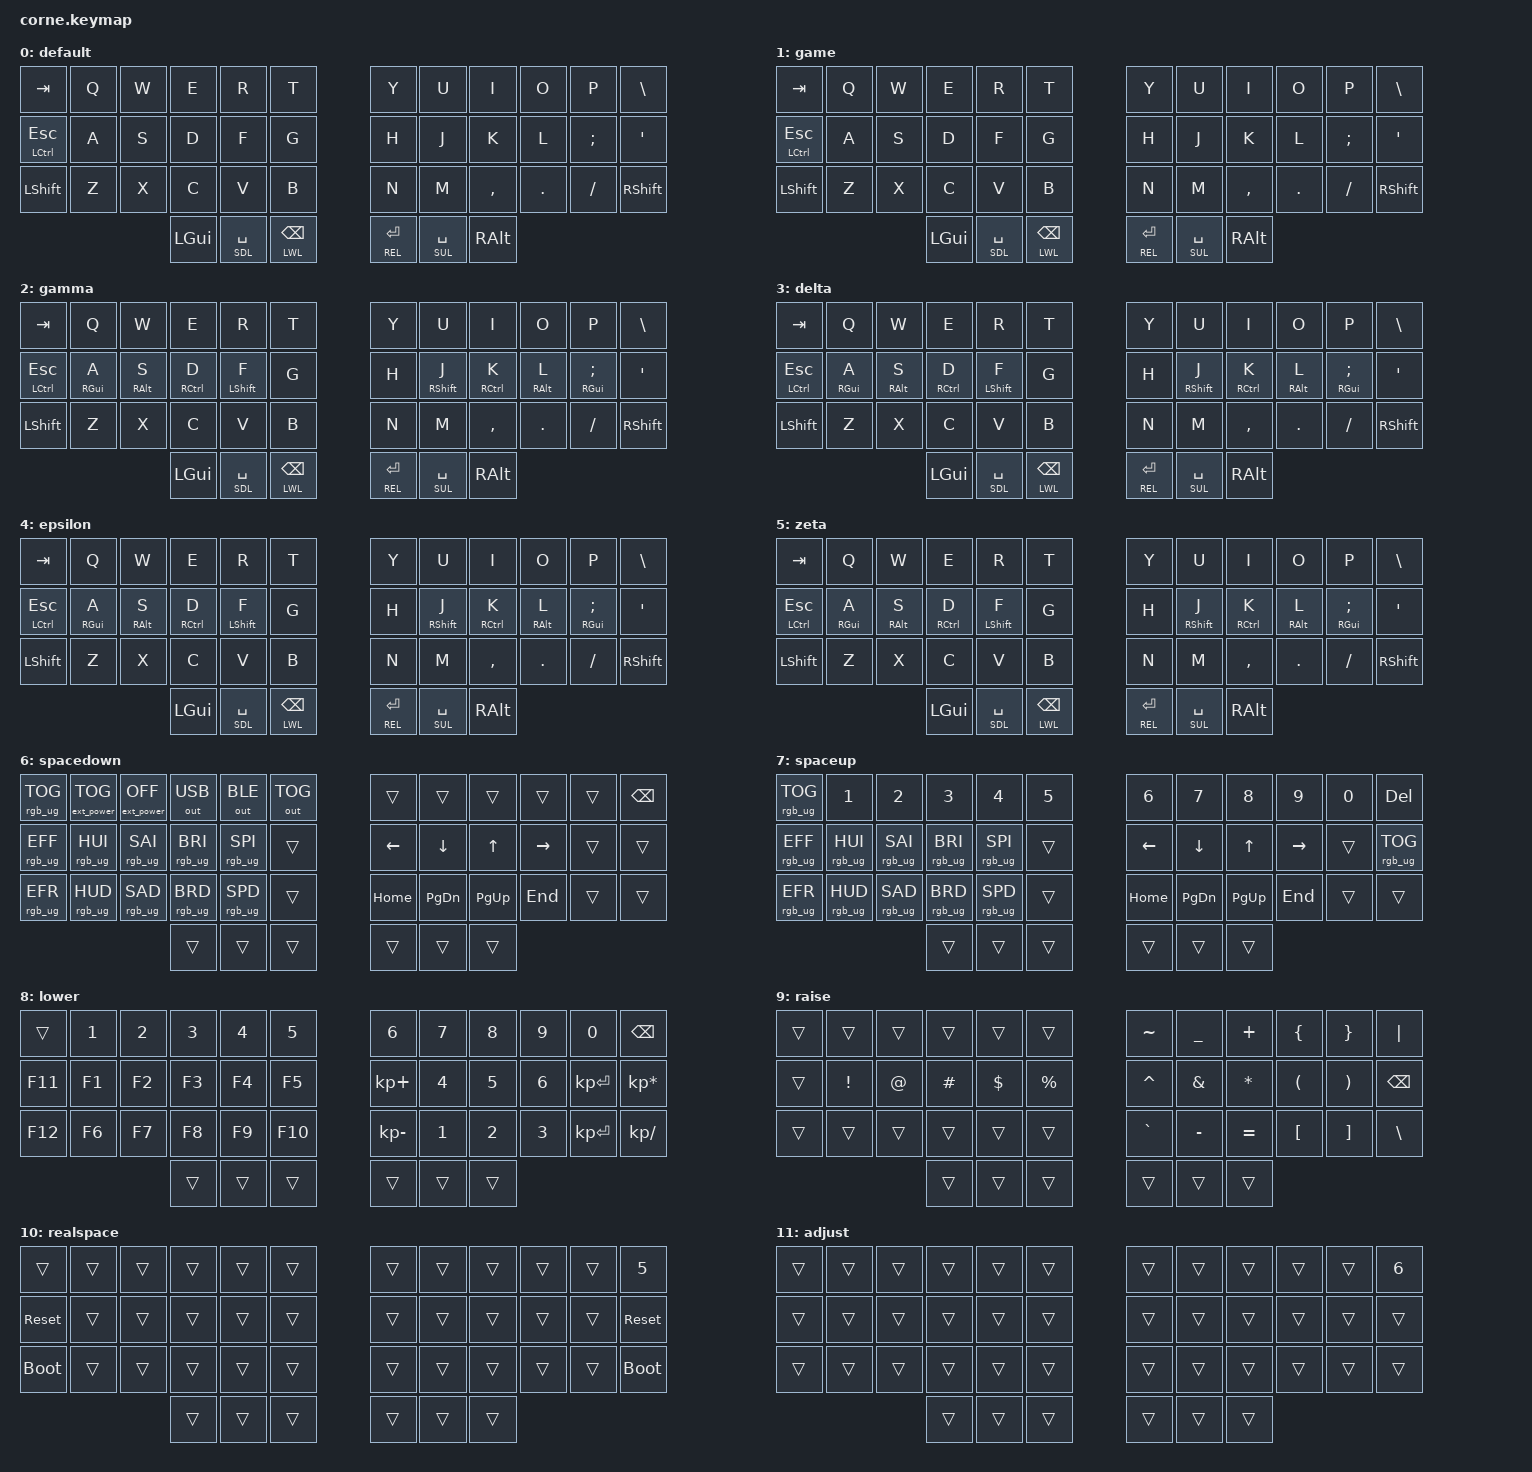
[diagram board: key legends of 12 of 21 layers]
/*
 * Copyright (c) 2020-2022 The ZMK Contributors
 *
 * SPDX-License-Identifier: MIT
 */

#include "behaviors.dtsi"
#include "dt-bindings/zmk/keys.h"

#include "dt-bindings/zmk/bt.h"
#include "dt-bindings/zmk/mouse.h"
#include "dt-bindings/zmk/outputs.h"
#include "dt-bindings/zmk/ext_power.h"
#include "dt-bindings/zmk/rgb.h"

#include "zmk-helpers/helper.h"
#include "zmk-helpers/key-labels/42.h"

#define DFL  0
#define GML  1
#define GAL  2
#define DTL  3
#define EPL  4
#define ZEL  5
#define SDL  6
#define SUL  7
#define LWL  8
#define REL  9
#define RSL 10
#define AJL 11
#define SSL 12
#define HSL 13
#define KSL 14
#define CSL 15
#define SLL 16
#define FSL 17
#define BHL 18
#define WHL 19
#define WPL 20

&spi3 {
  led_strip: ws2812@0 {
    /* WS2812 */
    chain-length = <27>; /* There are per-key RGB, but the first 6 are underglow */
  };
};

&mt {
  tapping-term-ms = <180>;
  flavor = "tap-preferred";
};
&lt {
  quick-tap-ms = <180>;
  tapping-term-ms = <200>;
  flavor = "balanced";
};

ZMK_CONDITIONAL_LAYER(SDL SUL, RSL) // spacedown + spaceup = realspace
ZMK_CONDITIONAL_LAYER(LWL REL, AJL) // lower + raise = adjust
ZMK_CONDITIONAL_LAYER(SDL LWL, SSL) // spacedown + lower = subspace
ZMK_CONDITIONAL_LAYER(SUL REL, HSL) // spaceup + raise = hyperspace
ZMK_CONDITIONAL_LAYER(SDL REL, KSL) // spacedown + raise = knownspace
ZMK_CONDITIONAL_LAYER(LWL SUL, CSL) // lower + spaceup = cyberspace
ZMK_CONDITIONAL_LAYER(SSL REL, SLL) // subspace + raise = slipspace
ZMK_CONDITIONAL_LAYER(LWL HSL, FSL) // lower + hyperspace = foldspace
ZMK_CONDITIONAL_LAYER(SSL SUL, BHL) // subspace + spaceup = blackhole
ZMK_CONDITIONAL_LAYER(SDL HSL, WHL) // spacedown + hyperspace = whitehole
ZMK_CONDITIONAL_LAYER(SSL HSL, WPL) // subspace + hyperspace = warp

ZMK_LAYER(default,
//    ┌───────────────┬───────┬───────┬──────────┬───────────────┬──────────────┬─────────────┬───────────────┬───────────┬─────────┬──────────┬───────────┐
        &kp TAB         &kp Q   &kp W   &kp E      &kp R           &kp T          &kp Y         &kp U           &kp I       &kp O     &kp P      &kp BSLH
//    ├───────────────┼───────┼───────┼──────────┼───────────────┼──────────────┼─────────────┼───────────────┼───────────┼─────────┼──────────┼───────────┤
        &mt LCTRL ESC   &kp A   &kp S   &kp D      &kp F           &kp G          &kp H         &kp J           &kp K       &kp L     &kp SEMI   &kp SQT
//    ├───────────────┼───────┼───────┼──────────┼───────────────┼──────────────┼─────────────┼───────────────┼───────────┼─────────┼──────────┼───────────┤
        &kp LSHFT       &kp Z   &kp X   &kp C      &kp V           &kp B          &kp N         &kp M           &kp COMMA   &kp DOT   &kp FSLH   &kp RSHFT
//    └───────────────┴───────┴───────┼──────────┼───────────────┼──────────────┼─────────────┼───────────────┼───────────┼─────────┴──────────┴───────────┘
                                        &kp LGUI   &lt SDL SPACE   &lt LWL BSPC   &lt REL RET   &lt SUL SPACE   &kp RALT
//                                    └──────────┴───────────────┴──────────────┴─────────────┴───────────────┴───────────┘
)

ZMK_LAYER(game,
//    ┌───────────────┬───────┬───────┬──────────┬───────────────┬──────────────┬─────────────┬───────────────┬───────────┬─────────┬──────────┬───────────┐
        &kp TAB         &kp Q   &kp W   &kp E      &kp R           &kp T          &kp Y         &kp U           &kp I       &kp O     &kp P      &kp BSLH
//    ├───────────────┼───────┼───────┼──────────┼───────────────┼──────────────┼─────────────┼───────────────┼───────────┼─────────┼──────────┼───────────┤
        &mt LCTRL ESC   &kp A   &kp S   &kp D      &kp F           &kp G          &kp H         &kp J           &kp K       &kp L     &kp SEMI   &kp SQT
//    ├───────────────┼───────┼───────┼──────────┼───────────────┼──────────────┼─────────────┼───────────────┼───────────┼─────────┼──────────┼───────────┤
        &kp LSHFT       &kp Z   &kp X   &kp C      &kp V           &kp B          &kp N         &kp M           &kp COMMA   &kp DOT   &kp FSLH   &kp RSHFT
//    └───────────────┴───────┴───────┼──────────┼───────────────┼──────────────┼─────────────┼───────────────┼───────────┼─────────┴──────────┴───────────┘
                                        &kp LGUI   &lt SDL SPACE   &lt LWL BSPC   &lt REL RET   &lt SUL SPACE   &kp RALT
//                                    └──────────┴───────────────┴──────────────┴─────────────┴───────────────┴───────────┘
)

ZMK_LAYER(gamma,
//    ┌───────────────┬────────────┬────────────┬─────────────┬───────────────┬──────────────┬─────────────┬───────────────┬─────────────┬────────────┬───────────────┬───────────┐
        &kp TAB         &kp Q        &kp W        &kp E         &kp R           &kp T          &kp Y         &kp U           &kp I         &kp O        &kp P           &kp BSLH
//    ├───────────────┼────────────┼────────────┼─────────────┼───────────────┼──────────────┼─────────────┼───────────────┼─────────────┼────────────┼───────────────┼───────────┤
        &mt LCTRL ESC   &mt RGUI A   &mt RALT S   &mt RCTRL D   &mt LSHFT F     &kp G          &kp H         &mt RSHFT J     &mt RCTRL K   &mt RALT L   &mt RGUI SEMI   &kp SQT
//    ├───────────────┼────────────┼────────────┼─────────────┼───────────────┼──────────────┼─────────────┼───────────────┼─────────────┼────────────┼───────────────┼───────────┤
        &kp LSHFT       &kp Z        &kp X        &kp C         &kp V           &kp B          &kp N         &kp M           &kp COMMA     &kp DOT      &kp FSLH        &kp RSHFT
//    └───────────────┴────────────┴────────────┼─────────────┼───────────────┼──────────────┼─────────────┼───────────────┼─────────────┼────────────┴───────────────┴───────────┘
                                                  &kp LGUI      &lt SDL SPACE   &lt LWL BSPC   &lt REL RET   &lt SUL SPACE   &kp RALT
//                                              └─────────────┴───────────────┴──────────────┴─────────────┴───────────────┴─────────────┘
)

ZMK_LAYER(delta,
//    ┌───────────────┬────────────┬────────────┬─────────────┬───────────────┬──────────────┬─────────────┬───────────────┬─────────────┬────────────┬───────────────┬───────────┐
        &kp TAB         &kp Q        &kp W        &kp E         &kp R           &kp T          &kp Y         &kp U           &kp I         &kp O        &kp P           &kp BSLH
//    ├───────────────┼────────────┼────────────┼─────────────┼───────────────┼──────────────┼─────────────┼───────────────┼─────────────┼────────────┼───────────────┼───────────┤
        &mt LCTRL ESC   &mt RGUI A   &mt RALT S   &mt RCTRL D   &mt LSHFT F     &kp G          &kp H         &mt RSHFT J     &mt RCTRL K   &mt RALT L   &mt RGUI SEMI   &kp SQT
//    ├───────────────┼────────────┼────────────┼─────────────┼───────────────┼──────────────┼─────────────┼───────────────┼─────────────┼────────────┼───────────────┼───────────┤
        &kp LSHFT       &kp Z        &kp X        &kp C         &kp V           &kp B          &kp N         &kp M           &kp COMMA     &kp DOT      &kp FSLH        &kp RSHFT
//    └───────────────┴────────────┴────────────┼─────────────┼───────────────┼──────────────┼─────────────┼───────────────┼─────────────┼────────────┴───────────────┴───────────┘
                                                  &kp LGUI      &lt SDL SPACE   &lt LWL BSPC   &lt REL RET   &lt SUL SPACE   &kp RALT
//                                              └─────────────┴───────────────┴──────────────┴─────────────┴───────────────┴─────────────┘
)

ZMK_LAYER(epsilon,
//    ┌───────────────┬────────────┬────────────┬─────────────┬───────────────┬──────────────┬─────────────┬───────────────┬─────────────┬────────────┬───────────────┬───────────┐
        &kp TAB         &kp Q        &kp W        &kp E         &kp R           &kp T          &kp Y         &kp U           &kp I         &kp O        &kp P           &kp BSLH
//    ├───────────────┼────────────┼────────────┼─────────────┼───────────────┼──────────────┼─────────────┼───────────────┼─────────────┼────────────┼───────────────┼───────────┤
        &mt LCTRL ESC   &mt RGUI A   &mt RALT S   &mt RCTRL D   &mt LSHFT F     &kp G          &kp H         &mt RSHFT J     &mt RCTRL K   &mt RALT L   &mt RGUI SEMI   &kp SQT
//    ├───────────────┼────────────┼────────────┼─────────────┼───────────────┼──────────────┼─────────────┼───────────────┼─────────────┼────────────┼───────────────┼───────────┤
        &kp LSHFT       &kp Z        &kp X        &kp C         &kp V           &kp B          &kp N         &kp M           &kp COMMA     &kp DOT      &kp FSLH        &kp RSHFT
//    └───────────────┴────────────┴────────────┼─────────────┼───────────────┼──────────────┼─────────────┼───────────────┼─────────────┼────────────┴───────────────┴───────────┘
                                                  &kp LGUI      &lt SDL SPACE   &lt LWL BSPC   &lt REL RET   &lt SUL SPACE   &kp RALT
//                                              └─────────────┴───────────────┴──────────────┴─────────────┴───────────────┴─────────────┘
)

ZMK_LAYER(zeta,
//    ┌───────────────┬────────────┬────────────┬─────────────┬───────────────┬──────────────┬─────────────┬───────────────┬─────────────┬────────────┬───────────────┬───────────┐
        &kp TAB         &kp Q        &kp W        &kp E         &kp R           &kp T          &kp Y         &kp U           &kp I         &kp O        &kp P           &kp BSLH
//    ├───────────────┼────────────┼────────────┼─────────────┼───────────────┼──────────────┼─────────────┼───────────────┼─────────────┼────────────┼───────────────┼───────────┤
        &mt LCTRL ESC   &mt RGUI A   &mt RALT S   &mt RCTRL D   &mt LSHFT F     &kp G          &kp H         &mt RSHFT J     &mt RCTRL K   &mt RALT L   &mt RGUI SEMI   &kp SQT
//    ├───────────────┼────────────┼────────────┼─────────────┼───────────────┼──────────────┼─────────────┼───────────────┼─────────────┼────────────┼───────────────┼───────────┤
        &kp LSHFT       &kp Z        &kp X        &kp C         &kp V           &kp B          &kp N         &kp M           &kp COMMA     &kp DOT      &kp FSLH        &kp RSHFT
//    └───────────────┴────────────┴────────────┼─────────────┼───────────────┼──────────────┼─────────────┼───────────────┼─────────────┼────────────┴───────────────┴───────────┘
                                                  &kp LGUI      &lt SDL SPACE   &lt LWL BSPC   &lt REL RET   &lt SUL SPACE   &kp RALT
//                                              └─────────────┴───────────────┴──────────────┴─────────────┴───────────────┴─────────────┘
)

ZMK_LAYER(spacedown,
//    ┌─────────────────┬───────────────────┬───────────────────┬─────────────────┬─────────────────┬──────────────┬──────────┬───────────┬───────────┬───────────┬────────┬──────────┐
        &rgb_ug RGB_TOG   &ext_power EP_TOG   &ext_power EP_OFF   &out OUT_USB      &out OUT_BLE      &out OUT_TOG   &trans     &trans      &trans      &trans      &trans   &kp BSPC
//    ├─────────────────┼───────────────────┼───────────────────┼─────────────────┼─────────────────┼──────────────┼──────────┼───────────┼───────────┼───────────┼────────┼──────────┤
        &rgb_ug RGB_EFF   &rgb_ug RGB_HUI     &rgb_ug RGB_SAI     &rgb_ug RGB_BRI   &rgb_ug RGB_SPI   &trans         &kp LEFT   &kp DOWN    &kp UP      &kp RIGHT   &trans   &trans
//    ├─────────────────┼───────────────────┼───────────────────┼─────────────────┼─────────────────┼──────────────┼──────────┼───────────┼───────────┼───────────┼────────┼──────────┤
        &rgb_ug RGB_EFR   &rgb_ug RGB_HUD     &rgb_ug RGB_SAD     &rgb_ug RGB_BRD   &rgb_ug RGB_SPD   &trans         &kp HOME   &kp PG_DN   &kp PG_UP   &kp END     &trans   &trans
//    └─────────────────┴───────────────────┴───────────────────┼─────────────────┼─────────────────┼──────────────┼──────────┼───────────┼───────────┼───────────┴────────┴──────────┘
                                                                  &trans            &trans            &trans         &trans     &trans      &trans
//                                                              └─────────────────┴─────────────────┴──────────────┴──────────┴───────────┴───────────┘
)

ZMK_LAYER(spaceup,
//    ┌─────────────────┬─────────────────┬─────────────────┬─────────────────┬─────────────────┬────────┬──────────┬───────────┬───────────┬───────────┬────────┬─────────────────┐
        &rgb_ug RGB_TOG   &kp N1            &kp N2            &kp N3            &kp N4            &kp N5   &kp N6     &kp N7      &kp N8      &kp N9      &kp N0   &kp DEL
//    ├─────────────────┼─────────────────┼─────────────────┼─────────────────┼─────────────────┼────────┼──────────┼───────────┼───────────┼───────────┼────────┼─────────────────┤
        &rgb_ug RGB_EFF   &rgb_ug RGB_HUI   &rgb_ug RGB_SAI   &rgb_ug RGB_BRI   &rgb_ug RGB_SPI   &trans   &kp LEFT   &kp DOWN    &kp UP      &kp RIGHT   &trans   &rgb_ug RGB_TOG
//    ├─────────────────┼─────────────────┼─────────────────┼─────────────────┼─────────────────┼────────┼──────────┼───────────┼───────────┼───────────┼────────┼─────────────────┤
        &rgb_ug RGB_EFR   &rgb_ug RGB_HUD   &rgb_ug RGB_SAD   &rgb_ug RGB_BRD   &rgb_ug RGB_SPD   &trans   &kp HOME   &kp PG_DN   &kp PG_UP   &kp END     &trans   &trans
//    └─────────────────┴─────────────────┴─────────────────┼─────────────────┼─────────────────┼────────┼──────────┼───────────┼───────────┼───────────┴────────┴─────────────────┘
                                                              &trans            &trans            &trans   &trans     &trans      &trans
//                                                          └─────────────────┴─────────────────┴────────┴──────────┴───────────┴───────────┘                                       
)

ZMK_LAYER(lower,
//    ┌─────────┬────────┬────────┬────────┬────────┬─────────┬──────────────┬────────┬────────┬────────┬──────────────┬─────────────────┐
        &trans    &kp N1   &kp N2   &kp N3   &kp N4   &kp N5    &kp N6         &kp N7   &kp N8   &kp N9   &kp N0         &kp BSPC
//    ├─────────┼────────┼────────┼────────┼────────┼─────────┼──────────────┼────────┼────────┼────────┼──────────────┼─────────────────┤
        &kp F11   &kp F1   &kp F2   &kp F3   &kp F4   &kp F5    &kp KP_PLUS    &kp N4   &kp N5   &kp N6   &kp KP_ENTER   &kp KP_MULTIPLY
//    ├─────────┼────────┼────────┼────────┼────────┼─────────┼──────────────┼────────┼────────┼────────┼──────────────┼─────────────────┤
        &kp F12   &kp F6   &kp F7   &kp F8   &kp F9   &kp F10   &kp KP_MINUS   &kp N1   &kp N2   &kp N3   &kp KP_ENTER   &kp KP_DIVIDE
//    └─────────┴────────┴────────┼────────┼────────┼─────────┼──────────────┼────────┼────────┼────────┴──────────────┴─────────────────┘
                                    &trans   &trans   &trans    &trans         &trans   &trans
//                                └────────┴────────┴─────────┴──────────────┴────────┴────────┘
)

ZMK_LAYER(raise,
//    ┌────────┬──────────┬────────┬──────────┬──────────┬───────────┬───────────┬───────────┬───────────┬──────────┬──────────┬──────────┐
        &trans   &trans     &trans   &trans     &trans     &trans      &kp TILDE   &kp UNDER   &kp PLUS    &kp LBRC   &kp RBRC   &kp PIPE
//    ├────────┼──────────┼────────┼──────────┼──────────┼───────────┼───────────┼───────────┼───────────┼──────────┼──────────┼──────────┤
        &trans   &kp EXCL   &kp AT   &kp HASH   &kp DLLR   &kp PRCNT   &kp CARET   &kp AMPS    &kp ASTRK   &kp LPAR   &kp RPAR   &kp BSPC
//    ├────────┼──────────┼────────┼──────────┼──────────┼───────────┼───────────┼───────────┼───────────┼──────────┼──────────┼──────────┤
        &trans   &trans     &trans   &trans     &trans     &trans      &kp GRAVE   &kp MINUS   &kp EQUAL   &kp LBKT   &kp RBKT   &kp BSLH
//    └────────┴──────────┴────────┼──────────┼──────────┼───────────┼───────────┼───────────┼───────────┼──────────┴──────────┴──────────┘
                                     &trans     &trans     &trans      &trans      &trans      &trans
//                                 └──────────┴──────────┴───────────┴───────────┴───────────┴───────────┘
)

ZMK_LAYER(realspace,
//    ┌─────────────┬────────┬────────┬────────┬────────┬────────┬────────┬────────┬────────┬────────┬────────┬─────────────┐
        &trans        &trans   &trans   &trans   &trans   &trans   &trans   &trans   &trans   &trans   &trans   &kp N5
//    ├─────────────┼────────┼────────┼────────┼────────┼────────┼────────┼────────┼────────┼────────┼────────┼─────────────┤
        &sys_reset    &trans   &trans   &trans   &trans   &trans   &trans   &trans   &trans   &trans   &trans   &sys_reset
//    ├─────────────┼────────┼────────┼────────┼────────┼────────┼────────┼────────┼────────┼────────┼────────┼─────────────┤
        &bootloader   &trans   &trans   &trans   &trans   &trans   &trans   &trans   &trans   &trans   &trans   &bootloader
//    └─────────────┴────────┴────────┼────────┼────────┼────────┼────────┼────────┼────────┼────────┴────────┴─────────────┘
                                        &trans   &trans   &trans   &trans   &trans   &trans
//                                    └────────┴────────┴────────┴────────┴────────┴────────┘
)

ZMK_LAYER(adjust,
//    ┌────────┬────────┬────────┬────────┬────────┬────────┬────────┬────────┬────────┬────────┬────────┬────────┐
        &trans   &trans   &trans   &trans   &trans   &trans   &trans   &trans   &trans   &trans   &trans   &kp N6
//    ├────────┼────────┼────────┼────────┼────────┼────────┼────────┼────────┼────────┼────────┼────────┼────────┤
        &trans   &trans   &trans   &trans   &trans   &trans   &trans   &trans   &trans   &trans   &trans   &trans
//    ├────────┼────────┼────────┼────────┼────────┼────────┼────────┼────────┼────────┼────────┼────────┼────────┤
        &trans   &trans   &trans   &trans   &trans   &trans   &trans   &trans   &trans   &trans   &trans   &trans
//    └────────┴────────┴────────┼────────┼────────┼────────┼────────┼────────┼────────┼────────┴────────┴────────┘
                                   &trans   &trans   &trans   &trans   &trans   &trans
//                               └────────┴────────┴────────┴────────┴────────┴────────┘
)

ZMK_LAYER(subspace,
//    ┌─────────────────┬──────────────┬──────────────┬──────────────┬──────────────┬──────────────┬────────┬────────┬────────┬────────┬────────┬────────┐
        &rgb_ug RGB_TOG   &trans         &trans         &out OUT_USB   &out OUT_BLE   &out OUT_TOG   &trans   &trans   &trans   &trans   &trans   &kp N7
//    ├─────────────────┼──────────────┼──────────────┼──────────────┼──────────────┼──────────────┼────────┼────────┼────────┼────────┼────────┼────────┤
        &bt BT_CLR        &bt BT_SEL 0   &bt BT_SEL 1   &bt BT_SEL 2   &bt BT_SEL 3   &bt BT_SEL 4   &trans   &trans   &trans   &trans   &trans   &trans
//    ├─────────────────┼──────────────┼──────────────┼──────────────┼──────────────┼──────────────┼────────┼────────┼────────┼────────┼────────┼────────┤
        &trans            &bt BT_SEL 5   &bt BT_SEL 6   &bt BT_SEL 7   &bt BT_SEL 8   &bt BT_SEL 9   &trans   &trans   &trans   &trans   &trans   &trans
//    └─────────────────┴──────────────┴──────────────┼──────────────┼──────────────┼──────────────┼────────┼────────┼────────┼────────┴────────┴────────┘
                                                        &trans         &trans         &trans         &trans   &trans   &trans
//                                                    └──────────────┴──────────────┴──────────────┴────────┴────────┴────────┘
)

ZMK_LAYER(hyperspace,
//    ┌─────────────────┬─────────────────┬─────────────────┬─────────────────┬─────────────────┬────────┬──────────┬───────────┬───────────┬───────────┬────────┬────────┐
        &rgb_ug RGB_TOG   &trans            &trans            &trans            &trans            &trans   &trans     &trans      &trans      &trans      &trans   &kp N8
//    ├─────────────────┼─────────────────┼─────────────────┼─────────────────┼─────────────────┼────────┼──────────┼───────────┼───────────┼───────────┼────────┼────────┤
        &rgb_ug RGB_EFF   &rgb_ug RGB_HUI   &rgb_ug RGB_SAI   &rgb_ug RGB_BRI   &rgb_ug RGB_SPI   &trans   &kp LEFT   &kp DOWN    &kp UP      &kp RIGHT   &trans   &trans
//    ├─────────────────┼─────────────────┼─────────────────┼─────────────────┼─────────────────┼────────┼──────────┼───────────┼───────────┼───────────┼────────┼────────┤
        &rgb_ug RGB_EFR   &rgb_ug RGB_HUD   &rgb_ug RGB_SAD   &rgb_ug RGB_BRD   &rgb_ug RGB_SPD   &trans   &kp HOME   &kp PG_DN   &kp PG_UP   &kp END     &trans   &trans
//    └─────────────────┴─────────────────┴─────────────────┼─────────────────┼─────────────────┼────────┼──────────┼───────────┼───────────┼───────────┴────────┴────────┘
                                                              &trans            &trans            &trans   &trans     &trans      &trans
//                                                          └─────────────────┴─────────────────┴────────┴──────────┴───────────┴───────────┘
)

ZMK_LAYER(knownspace,
//    ┌────────┬────────┬────────┬────────┬────────┬────────┬────────┬────────┬────────┬────────┬────────┬────────┐
        &trans   &trans   &trans   &trans   &trans   &trans   &trans   &trans   &trans   &trans   &trans   &trans
//    ├────────┼────────┼────────┼────────┼────────┼────────┼────────┼────────┼────────┼────────┼────────┼────────┤
        &trans   &trans   &trans   &trans   &trans   &trans   &trans   &trans   &trans   &trans   &trans   &trans
//    ├────────┼────────┼────────┼────────┼────────┼────────┼────────┼────────┼────────┼────────┼────────┼────────┤
        &trans   &trans   &trans   &trans   &trans   &trans   &trans   &trans   &trans   &trans   &trans   &trans
//    └────────┴────────┴────────┼────────┼────────┼────────┼────────┼────────┼────────┼────────┴────────┴────────┘
                                   &trans   &trans   &trans   &trans   &trans   &trans
//                               └────────┴────────┴────────┴────────┴────────┴────────┘
)

ZMK_LAYER(cyberspace,
//    ┌────────┬────────┬────────┬────────┬────────┬────────┬────────┬────────┬────────┬────────┬────────┬────────┐
        &trans   &trans   &trans   &trans   &trans   &trans   &trans   &trans   &trans   &trans   &trans   &trans
//    ├────────┼────────┼────────┼────────┼────────┼────────┼────────┼────────┼────────┼────────┼────────┼────────┤
        &trans   &trans   &trans   &trans   &trans   &trans   &trans   &trans   &trans   &trans   &trans   &trans
//    ├────────┼────────┼────────┼────────┼────────┼────────┼────────┼────────┼────────┼────────┼────────┼────────┤
        &trans   &trans   &trans   &trans   &trans   &trans   &trans   &trans   &trans   &trans   &trans   &trans
//    └────────┴────────┴────────┼────────┼────────┼────────┼────────┼────────┼────────┼────────┴────────┴────────┘
                                   &trans   &trans   &trans   &trans   &trans   &trans
//                               └────────┴────────┴────────┴────────┴────────┴────────┘
)

ZMK_LAYER(slipspace,
//    ┌────────┬────────┬────────┬────────┬────────┬────────┬────────┬────────┬────────┬────────┬────────┬────────┐
        &trans   &trans   &trans   &trans   &trans   &trans   &trans   &trans   &trans   &trans   &trans   &trans
//    ├────────┼────────┼────────┼────────┼────────┼────────┼────────┼────────┼────────┼────────┼────────┼────────┤
        &trans   &trans   &trans   &trans   &trans   &trans   &trans   &trans   &trans   &trans   &trans   &trans
//    ├────────┼────────┼────────┼────────┼────────┼────────┼────────┼────────┼────────┼────────┼────────┼────────┤
        &trans   &trans   &trans   &trans   &trans   &trans   &trans   &trans   &trans   &trans   &trans   &trans
//    └────────┴────────┴────────┼────────┼────────┼────────┼────────┼────────┼────────┼────────┴────────┴────────┘
                                   &trans   &trans   &trans   &trans   &trans   &trans
//                               └────────┴────────┴────────┴────────┴────────┴────────┘
)

ZMK_LAYER(foldspace,
//    ┌────────┬────────┬────────┬────────┬────────┬────────┬────────┬────────┬────────┬────────┬────────┬────────┐
        &trans   &trans   &trans   &trans   &trans   &trans   &trans   &trans   &trans   &trans   &trans   &trans
//    ├────────┼────────┼────────┼────────┼────────┼────────┼────────┼────────┼────────┼────────┼────────┼────────┤
        &trans   &trans   &trans   &trans   &trans   &trans   &trans   &trans   &trans   &trans   &trans   &trans
//    ├────────┼────────┼────────┼────────┼────────┼────────┼────────┼────────┼────────┼────────┼────────┼────────┤
        &trans   &trans   &trans   &trans   &trans   &trans   &trans   &trans   &trans   &trans   &trans   &trans
//    └────────┴────────┴────────┼────────┼────────┼────────┼────────┼────────┼────────┼────────┴────────┴────────┘
                                   &trans   &trans   &trans   &trans   &trans   &trans
//                               └────────┴────────┴────────┴────────┴────────┴────────┘
)

ZMK_LAYER(blackhole,
//    ┌────────┬────────┬────────┬────────┬────────┬────────┬────────┬────────┬────────┬────────┬────────┬────────┐
        &trans   &trans   &trans   &trans   &trans   &trans   &trans   &trans   &trans   &trans   &trans   &trans
//    ├────────┼────────┼────────┼────────┼────────┼────────┼────────┼────────┼────────┼────────┼────────┼────────┤
        &trans   &trans   &trans   &trans   &trans   &trans   &trans   &trans   &trans   &trans   &trans   &trans
//    ├────────┼────────┼────────┼────────┼────────┼────────┼────────┼────────┼────────┼────────┼────────┼────────┤
        &trans   &trans   &trans   &trans   &trans   &trans   &trans   &trans   &trans   &trans   &trans   &trans
//    └────────┴────────┴────────┼────────┼────────┼────────┼────────┼────────┼────────┼────────┴────────┴────────┘
                                   &trans   &trans   &trans   &trans   &trans   &trans
//                               └────────┴────────┴────────┴────────┴────────┴────────┘
)

ZMK_LAYER(wormhole,
//    ┌────────┬────────┬────────┬────────┬────────┬────────┬────────┬────────┬────────┬────────┬────────┬────────┐
        &trans   &trans   &trans   &trans   &trans   &trans   &trans   &trans   &trans   &trans   &trans   &trans
//    ├────────┼────────┼────────┼────────┼────────┼────────┼────────┼────────┼────────┼────────┼────────┼────────┤
        &trans   &trans   &trans   &trans   &trans   &trans   &trans   &trans   &trans   &trans   &trans   &trans
//    ├────────┼────────┼────────┼────────┼────────┼────────┼────────┼────────┼────────┼────────┼────────┼────────┤
        &trans   &trans   &trans   &trans   &trans   &trans   &trans   &trans   &trans   &trans   &trans   &trans
//    └────────┴────────┴────────┼────────┼────────┼────────┼────────┼────────┼────────┼────────┴────────┴────────┘
                                   &trans   &trans   &trans   &trans   &trans   &trans
//                               └────────┴────────┴────────┴────────┴────────┴────────┘
)

ZMK_LAYER(warp,
//    ┌────────┬────────┬────────┬────────┬────────┬────────┬────────┬────────┬────────┬────────┬────────┬────────┐
        &trans   &trans   &trans   &trans   &trans   &trans   &trans   &trans   &trans   &trans   &trans   &trans
//    ├────────┼────────┼────────┼────────┼────────┼────────┼────────┼────────┼────────┼────────┼────────┼────────┤
        &trans   &trans   &trans   &trans   &trans   &trans   &trans   &trans   &trans   &trans   &trans   &trans
//    ├────────┼────────┼────────┼────────┼────────┼────────┼────────┼────────┼────────┼────────┼────────┼────────┤
        &trans   &trans   &trans   &trans   &trans   &trans   &trans   &trans   &trans   &trans   &trans   &trans
//    └────────┴────────┴────────┼────────┼────────┼────────┼────────┼────────┼────────┼────────┴────────┴────────┘
                                   &trans   &trans   &trans   &trans   &trans   &trans
//                               └────────┴────────┴────────┴────────┴────────┴────────┘
)
